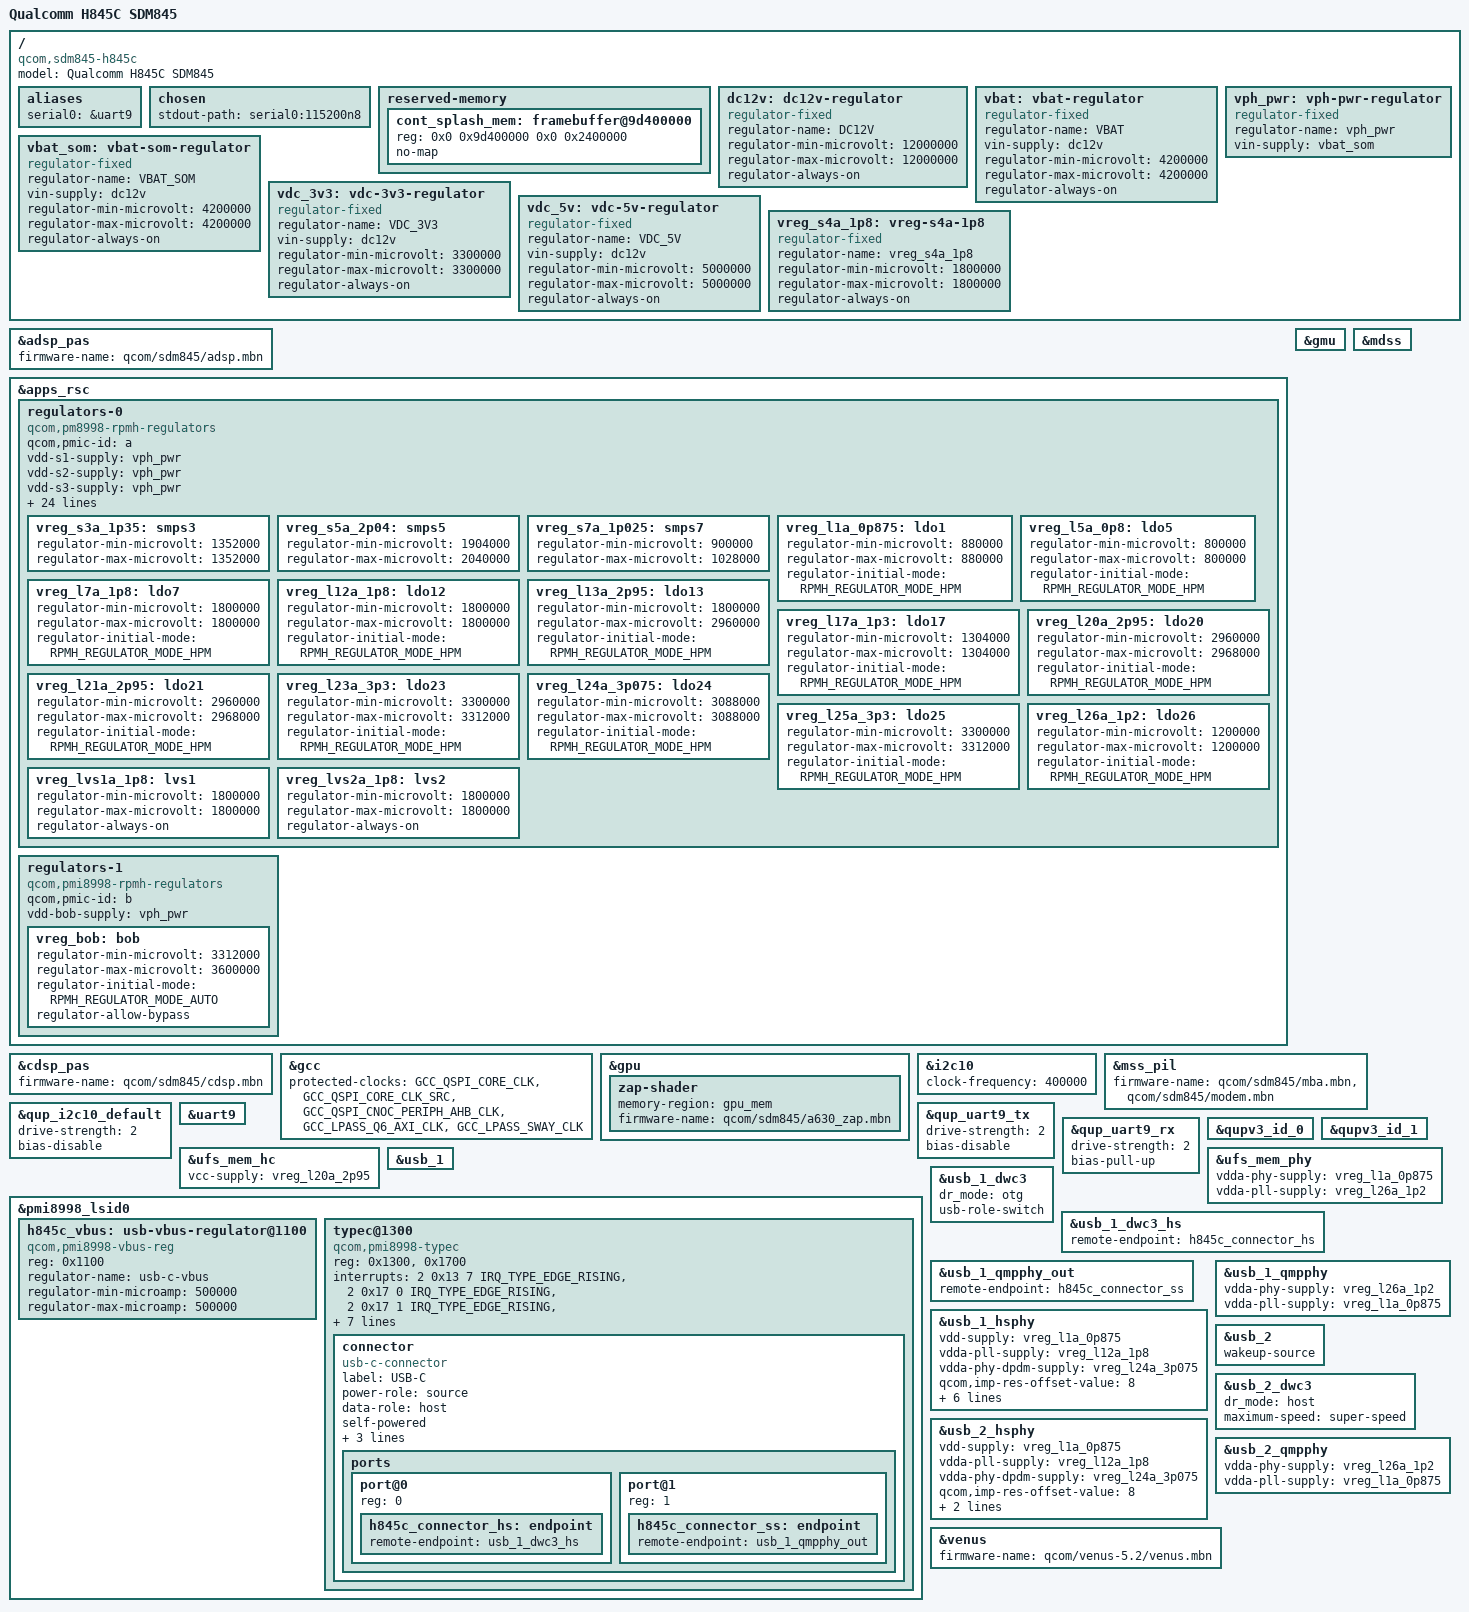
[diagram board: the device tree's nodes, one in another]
// SPDX-License-Identifier: GPL-2.0
/*
 * Baidu H845C (Qualcomm SDM845) initial mainline device tree.
 * Reconstructed from upstream SDM845/PM8998/PMI8998 DTSI and verified
 * board-level differences in the running sdm845-h845c.dtb.
 */

/dts-v1/;

#include <dt-bindings/interrupt-controller/irq.h>
#include <dt-bindings/phy/phy-qcom-qusb2.h>
#include <dt-bindings/regulator/qcom,rpmh-regulator.h>
#include "sdm845.dtsi"
#include "pm8998.dtsi"
#include "pmi8998.dtsi"

/ {
	model = "Qualcomm H845C SDM845";
	compatible = "qcom,sdm845-h845c", "qcom,sdm845";

	aliases {
		serial0 = &uart9;
	};

	chosen {
		stdout-path = "serial0:115200n8";
	};

	reserved-memory {
		cont_splash_mem: framebuffer@9d400000 {
			reg = <0x0 0x9d400000 0x0 0x2400000>;
			no-map;
		};
	};

	dc12v: dc12v-regulator {
		compatible = "regulator-fixed";
		regulator-name = "DC12V";
		regulator-min-microvolt = <12000000>;
		regulator-max-microvolt = <12000000>;
		regulator-always-on;
	};

	vbat: vbat-regulator {
		compatible = "regulator-fixed";
		regulator-name = "VBAT";
		vin-supply = <&dc12v>;
		regulator-min-microvolt = <4200000>;
		regulator-max-microvolt = <4200000>;
		regulator-always-on;
	};

	vbat_som: vbat-som-regulator {
		compatible = "regulator-fixed";
		regulator-name = "VBAT_SOM";
		vin-supply = <&dc12v>;
		regulator-min-microvolt = <4200000>;
		regulator-max-microvolt = <4200000>;
		regulator-always-on;
	};

	vdc_3v3: vdc-3v3-regulator {
		compatible = "regulator-fixed";
		regulator-name = "VDC_3V3";
		vin-supply = <&dc12v>;
		regulator-min-microvolt = <3300000>;
		regulator-max-microvolt = <3300000>;
		regulator-always-on;
	};

	vdc_5v: vdc-5v-regulator {
		compatible = "regulator-fixed";
		regulator-name = "VDC_5V";
		vin-supply = <&dc12v>;
		regulator-min-microvolt = <5000000>;
		regulator-max-microvolt = <5000000>;
		regulator-always-on;
	};

	vreg_s4a_1p8: vreg-s4a-1p8 {
		compatible = "regulator-fixed";
		regulator-name = "vreg_s4a_1p8";
		regulator-min-microvolt = <1800000>;
		regulator-max-microvolt = <1800000>;
		regulator-always-on;
	};

	vph_pwr: vph-pwr-regulator {
		compatible = "regulator-fixed";
		regulator-name = "vph_pwr";
		vin-supply = <&vbat_som>;
	};
};

&adsp_pas {
	status = "okay";
	firmware-name = "qcom/sdm845/adsp.mbn";
};

&apps_rsc {
	regulators-0 {
		compatible = "qcom,pm8998-rpmh-regulators";
		qcom,pmic-id = "a";

		vdd-s1-supply = <&vph_pwr>;
		vdd-s2-supply = <&vph_pwr>;
		vdd-s3-supply = <&vph_pwr>;
		vdd-s4-supply = <&vph_pwr>;
		vdd-s5-supply = <&vph_pwr>;
		vdd-s6-supply = <&vph_pwr>;
		vdd-s7-supply = <&vph_pwr>;
		vdd-s8-supply = <&vph_pwr>;
		vdd-s9-supply = <&vph_pwr>;
		vdd-s10-supply = <&vph_pwr>;
		vdd-s11-supply = <&vph_pwr>;
		vdd-s12-supply = <&vph_pwr>;
		vdd-s13-supply = <&vph_pwr>;
		vdd-l1-l27-supply = <&vreg_s7a_1p025>;
		vdd-l2-l8-l17-supply = <&vreg_s3a_1p35>;
		vdd-l3-l11-supply = <&vreg_s7a_1p025>;
		vdd-l4-l5-supply = <&vreg_s7a_1p025>;
		vdd-l6-supply = <&vph_pwr>;
		vdd-l7-l12-l14-l15-supply = <&vreg_s5a_2p04>;
		vdd-l9-supply = <&vreg_bob>;
		vdd-l10-l23-l25-supply = <&vreg_bob>;
		vdd-l13-l19-l21-supply = <&vreg_bob>;
		vdd-l16-l28-supply = <&vreg_bob>;
		vdd-l18-l22-supply = <&vreg_bob>;
		vdd-l20-l24-supply = <&vreg_bob>;
		vdd-l26-supply = <&vreg_s3a_1p35>;
		vin-lvs-1-2-supply = <&vreg_s4a_1p8>;

		vreg_s3a_1p35: smps3 {
			regulator-min-microvolt = <1352000>;
			regulator-max-microvolt = <1352000>;
		};

		vreg_s5a_2p04: smps5 {
			regulator-min-microvolt = <1904000>;
			regulator-max-microvolt = <2040000>;
		};

		vreg_s7a_1p025: smps7 {
			regulator-min-microvolt = <900000>;
			regulator-max-microvolt = <1028000>;
		};

		vreg_l1a_0p875: ldo1 {
			regulator-min-microvolt = <880000>;
			regulator-max-microvolt = <880000>;
			regulator-initial-mode = <RPMH_REGULATOR_MODE_HPM>;
		};

		vreg_l5a_0p8: ldo5 {
			regulator-min-microvolt = <800000>;
			regulator-max-microvolt = <800000>;
			regulator-initial-mode = <RPMH_REGULATOR_MODE_HPM>;
		};

		vreg_l7a_1p8: ldo7 {
			regulator-min-microvolt = <1800000>;
			regulator-max-microvolt = <1800000>;
			regulator-initial-mode = <RPMH_REGULATOR_MODE_HPM>;
		};

		vreg_l12a_1p8: ldo12 {
			regulator-min-microvolt = <1800000>;
			regulator-max-microvolt = <1800000>;
			regulator-initial-mode = <RPMH_REGULATOR_MODE_HPM>;
		};

		vreg_l13a_2p95: ldo13 {
			regulator-min-microvolt = <1800000>;
			regulator-max-microvolt = <2960000>;
			regulator-initial-mode = <RPMH_REGULATOR_MODE_HPM>;
		};

		vreg_l17a_1p3: ldo17 {
			regulator-min-microvolt = <1304000>;
			regulator-max-microvolt = <1304000>;
			regulator-initial-mode = <RPMH_REGULATOR_MODE_HPM>;
		};

		vreg_l20a_2p95: ldo20 {
			regulator-min-microvolt = <2960000>;
			regulator-max-microvolt = <2968000>;
			regulator-initial-mode = <RPMH_REGULATOR_MODE_HPM>;
		};

		vreg_l21a_2p95: ldo21 {
			regulator-min-microvolt = <2960000>;
			regulator-max-microvolt = <2968000>;
			regulator-initial-mode = <RPMH_REGULATOR_MODE_HPM>;
		};

		vreg_l23a_3p3: ldo23 {
			regulator-min-microvolt = <3300000>;
			regulator-max-microvolt = <3312000>;
			regulator-initial-mode = <RPMH_REGULATOR_MODE_HPM>;
		};

		vreg_l24a_3p075: ldo24 {
			regulator-min-microvolt = <3088000>;
			regulator-max-microvolt = <3088000>;
			regulator-initial-mode = <RPMH_REGULATOR_MODE_HPM>;
		};

		vreg_l25a_3p3: ldo25 {
			regulator-min-microvolt = <3300000>;
			regulator-max-microvolt = <3312000>;
			regulator-initial-mode = <RPMH_REGULATOR_MODE_HPM>;
		};

		vreg_l26a_1p2: ldo26 {
			regulator-min-microvolt = <1200000>;
			regulator-max-microvolt = <1200000>;
			regulator-initial-mode = <RPMH_REGULATOR_MODE_HPM>;
		};

		vreg_lvs1a_1p8: lvs1 {
			regulator-min-microvolt = <1800000>;
			regulator-max-microvolt = <1800000>;
			regulator-always-on;
		};

		vreg_lvs2a_1p8: lvs2 {
			regulator-min-microvolt = <1800000>;
			regulator-max-microvolt = <1800000>;
			regulator-always-on;
		};
	};

	regulators-1 {
		compatible = "qcom,pmi8998-rpmh-regulators";
		qcom,pmic-id = "b";

		vdd-bob-supply = <&vph_pwr>;

		vreg_bob: bob {
			regulator-min-microvolt = <3312000>;
			regulator-max-microvolt = <3600000>;
			regulator-initial-mode = <RPMH_REGULATOR_MODE_AUTO>;
			regulator-allow-bypass;
		};
	};
};

&cdsp_pas {
	status = "okay";
	firmware-name = "qcom/sdm845/cdsp.mbn";
};

&gcc {
	protected-clocks = <GCC_QSPI_CORE_CLK>,
			   <GCC_QSPI_CORE_CLK_SRC>,
			   <GCC_QSPI_CNOC_PERIPH_AHB_CLK>,
			   <GCC_LPASS_Q6_AXI_CLK>,
			   <GCC_LPASS_SWAY_CLK>;
};

&gmu {
	status = "okay";
};

&gpu {
	status = "okay";

	zap-shader {
		memory-region = <&gpu_mem>;
		firmware-name = "qcom/sdm845/a630_zap.mbn";
	};
};

&i2c10 {
	status = "okay";
	clock-frequency = <400000>;
};

&mdss {
	status = "okay";
};

&mss_pil {
	status = "okay";
	firmware-name = "qcom/sdm845/mba.mbn", "qcom/sdm845/modem.mbn";
};

/*
 * The vendor DT names PMI8998 GPIO2 and GPIO10 as boost enables but has
 * no consumer for either pin. USB-C VBUS uses the SMB2 regulator below.
 */

&qup_i2c10_default {
	drive-strength = <2>;
	bias-disable;
};

&qup_uart9_tx {
	drive-strength = <2>;
	bias-disable;
};

&qup_uart9_rx {
	drive-strength = <2>;
	bias-pull-up;
};

&qupv3_id_0 {
	status = "okay";
};

&qupv3_id_1 {
	status = "okay";
};

&uart9 {
	status = "okay";
};

&ufs_mem_hc {
	status = "okay";
	vcc-supply = <&vreg_l20a_2p95>;
};

&ufs_mem_phy {
	status = "okay";
	vdda-phy-supply = <&vreg_l1a_0p875>;
	vdda-pll-supply = <&vreg_l26a_1p2>;
};

&usb_1 {
	status = "okay";
};

&pmi8998_lsid0 {
	h845c_vbus: usb-vbus-regulator@1100 {
		compatible = "qcom,pmi8998-vbus-reg";
		reg = <0x1100>;
		regulator-name = "usb-c-vbus";
		regulator-min-microamp = <500000>;
		regulator-max-microamp = <500000>;
	};

	typec@1300 {
		compatible = "qcom,pmi8998-typec";
		reg = <0x1300>, <0x1700>;
		interrupts = <2 0x13 7 IRQ_TYPE_EDGE_RISING>,
			     <2 0x17 0 IRQ_TYPE_EDGE_RISING>,
			     <2 0x17 1 IRQ_TYPE_EDGE_RISING>,
			     <2 0x17 2 IRQ_TYPE_EDGE_RISING>,
			     <2 0x17 3 IRQ_TYPE_EDGE_RISING>,
			     <2 0x17 4 IRQ_TYPE_EDGE_RISING>,
			     <2 0x17 5 IRQ_TYPE_EDGE_RISING>,
			     <2 0x17 6 IRQ_TYPE_EDGE_RISING>,
			     <2 0x17 7 IRQ_TYPE_EDGE_RISING>;
		interrupt-names = "type-c-change", "sig-tx", "sig-rx", "msg-tx",
				  "msg-rx", "msg-tx-failed", "msg-tx-discarded",
				  "msg-rx-discarded", "fr-swap";
		vdd-pdphy-supply = <&vreg_l24a_3p075>;

		connector {
			compatible = "usb-c-connector";
			label = "USB-C";
			power-role = "source";
			data-role = "host";
			self-powered;
			pd-disable;
			typec-power-opmode = "default";
			vbus-supply = <&h845c_vbus>;

			ports {
				#address-cells = <1>;
				#size-cells = <0>;
				port@0 {
					reg = <0>;
					h845c_connector_hs: endpoint {
						remote-endpoint = <&usb_1_dwc3_hs>;
					};
				};
				port@1 {
					reg = <1>;
					h845c_connector_ss: endpoint {
						remote-endpoint = <&usb_1_qmpphy_out>;
					};
				};
			};
		};
	};
};

&usb_1_dwc3 {
	dr_mode = "otg";
	usb-role-switch;
};

&usb_1_dwc3_hs {
	remote-endpoint = <&h845c_connector_hs>;
};

&usb_1_qmpphy_out {
	remote-endpoint = <&h845c_connector_ss>;
};

&usb_1_hsphy {
	status = "okay";

	vdd-supply = <&vreg_l1a_0p875>;
	vdda-pll-supply = <&vreg_l12a_1p8>;
	vdda-phy-dpdm-supply = <&vreg_l24a_3p075>;

	qcom,imp-res-offset-value = <8>;
	qcom,hstx-trim-value = <QUSB2_V2_HSTX_TRIM_21_6_MA>;
	qcom,preemphasis-level = <QUSB2_V2_PREEMPHASIS_5_PERCENT>;
	qcom,preemphasis-width = <QUSB2_V2_PREEMPHASIS_WIDTH_HALF_BIT>;
};

&usb_1_qmpphy {
	status = "okay";

	vdda-phy-supply = <&vreg_l26a_1p2>;
	vdda-pll-supply = <&vreg_l1a_0p875>;
};

&usb_2 {
	status = "okay";
	wakeup-source;
};

&usb_2_dwc3 {
	dr_mode = "host";
	maximum-speed = "super-speed";
};

&usb_2_hsphy {
	status = "okay";

	vdd-supply = <&vreg_l1a_0p875>;
	vdda-pll-supply = <&vreg_l12a_1p8>;
	vdda-phy-dpdm-supply = <&vreg_l24a_3p075>;

	qcom,imp-res-offset-value = <8>;
	qcom,hstx-trim-value = <QUSB2_V2_HSTX_TRIM_22_8_MA>;
};

&usb_2_qmpphy {
	status = "okay";

	vdda-phy-supply = <&vreg_l26a_1p2>;
	vdda-pll-supply = <&vreg_l1a_0p875>;
};

&venus {
	status = "okay";
	firmware-name = "qcom/venus-5.2/venus.mbn";
};
